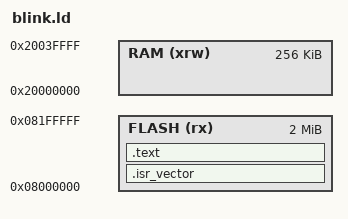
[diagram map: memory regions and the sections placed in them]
ENTRY(Reset_Handler)

MEMORY
{
    FLASH (rx) : ORIGIN = 0x08000000, LENGTH = 2048K
    RAM (xrw)  : ORIGIN = 0x20000000, LENGTH = 256K
}

SECTIONS
{
    .isr_vector : {
        KEEP(*(.isr_vector))
    } > FLASH

    .text : {
        *(.text*)
        *(.rodata*)
    } > FLASH
}
